VERSION ""

NS_ :

BS_:

BU_: FLZCU_VCU_EP FLZCU_PDCS_EP FLZCU_EP VCU_EP FLZCU_SignalRoute_EP BMS CDU FMCU_ISG FMCU ISG RMCU RMCU_E0V EVCC PDCS_EP PDCS_EP_E0V CIC_EP RmcuCdu RmcuCdu_E0V FmcuVcu_EP FmcuVcu_EP_E0V

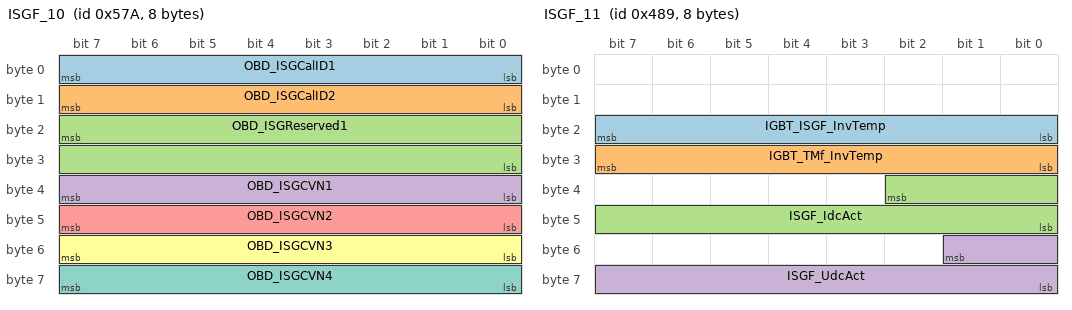
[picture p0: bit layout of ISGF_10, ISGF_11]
BO_ 1402 ISGF_10: 8 FMCU_ISG
 SG_ OBD_ISGCalID1 : 7|8@0+ (1,0) [0|255] ""  Vector__XXX
 SG_ OBD_ISGCalID2 : 15|8@0+ (1,0) [0|255] ""  Vector__XXX
 SG_ OBD_ISGReserved1 : 23|16@0+ (1,0) [0|65535] ""  Vector__XXX
 SG_ OBD_ISGCVN1 : 39|8@0+ (1,0) [0|255] ""  Vector__XXX
 SG_ OBD_ISGCVN2 : 47|8@0+ (1,0) [0|255] ""  Vector__XXX
 SG_ OBD_ISGCVN3 : 55|8@0+ (1,0) [0|255] ""  Vector__XXX
 SG_ OBD_ISGCVN4 : 63|8@0+ (1,0) [0|255] ""  Vector__XXX

BO_ 1161 ISGF_11: 8 FMCU_ISG
 SG_ IGBT_ISGF_InvTemp : 23|8@0+ (1,-40) [-40|213] "oC"  FLZCU_VCU_EP,VCU_EP,PDCS_EP,PDCS_EP_E0V
 SG_ IGBT_TMf_InvTemp : 31|8@0+ (1,-40) [-40|213] "oC"  Vector__XXX
 SG_ ISGF_IdcAct : 34|11@0+ (1,-1023) [-1023|1021] "A"  Vector__XXX
 SG_ ISGF_UdcAct : 49|10@0+ (1,0) [0|1021] "V"  Vector__XXX

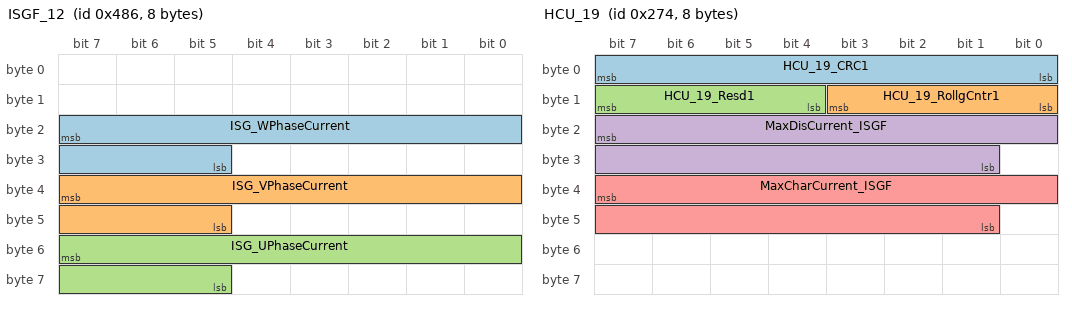
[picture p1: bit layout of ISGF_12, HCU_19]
BO_ 1158 ISGF_12: 8 FMCU_ISG
 SG_ ISG_WPhaseCurrent : 23|11@0+ (1,-1023) [-1023|1023] "A"  Vector__XXX
 SG_ ISG_VPhaseCurrent : 39|11@0+ (1,-1023) [-1023|1023] "A"  Vector__XXX
 SG_ ISG_UPhaseCurrent : 55|11@0+ (1,-1023) [-1023|1023] "A"  Vector__XXX

BO_ 327 ISGF_13: 24 FMCU_ISG
 SG_ ISGF_13_CRC : 7|8@0+ (1,0) [0|255] ""  FLZCU_VCU_EP,FLZCU_PDCS_EP,VCU_EP,PDCS_EP,PDCS_EP_E0V
 SG_ ISGF_13_RollgCntr : 11|4@0+ (1,0) [0|14] ""  FLZCU_VCU_EP,FLZCU_PDCS_EP,VCU_EP,PDCS_EP,PDCS_EP_E0V
 SG_ ISGF_IdcAct : 23|11@0+ (1,-1023) [-1023|1021] "A"  FLZCU_VCU_EP,FLZCU_PDCS_EP,VCU_EP,PDCS_EP,PDCS_EP_E0V
 SG_ ISGF_UdcAct : 39|10@0+ (1,0) [0|1021] "V"  FLZCU_VCU_EP,FLZCU_PDCS_EP,VCU_EP,PDCS_EP,PDCS_EP_E0V
 SG_ ISGF_ErrLvl : 27|4@0+ (1,0) [0|4] ""  FLZCU_VCU_EP,FLZCU_PDCS_EP,VCU_EP,PDCS_EP,PDCS_EP_E0V
 SG_ ISGF_VoltageT30 : 45|6@0+ (0.5,0) [0|31] "V"  FLZCU_VCU_EP,FLZCU_PDCS_EP,VCU_EP,PDCS_EP,PDCS_EP_E0V
 SG_ ISGF_DischargeState : 55|2@0+ (1,0) [0|3] ""  FLZCU_VCU_EP,FLZCU_PDCS_EP,VCU_EP,PDCS_EP,PDCS_EP_E0V
 SG_ ISGF_TrqActDampingReq : 50|11@0+ (0.25,-255) [-255|255] "Nm"  FLZCU_VCU_EP,FLZCU_PDCS_EP,VCU_EP,PDCS_EP,PDCS_EP_E0V
 SG_ ISGF_DampActive : 53|1@0+ (1,0) [0|1] ""  FLZCU_VCU_EP,FLZCU_PDCS_EP,VCU_EP,PDCS_EP,PDCS_EP_E0V
 SG_ ISGF_FlowReq : 87|8@0+ (0.1,0) [0|25.4] "L/min"  FLZCU_VCU_EP,FLZCU_PDCS_EP,VCU_EP,PDCS_EP,PDCS_EP_E0V
 SG_ ISGF_GateDrvSt : 95|2@0+ (1,0) [0|3] ""  FLZCU_VCU_EP,FLZCU_PDCS_EP,VCU_EP,PDCS_EP,PDCS_EP_E0V
 SG_ ISGF_WPhaseCurrent : 93|11@0+ (1,-1023) [-1023|1023] "A"  FLZCU_VCU_EP,FLZCU_PDCS_EP,VCU_EP,PDCS_EP,PDCS_EP_E0V
 SG_ ISGF_VPhaseCurrent : 98|11@0+ (1,-1023) [-1023|1023] "A"  FLZCU_VCU_EP,FLZCU_PDCS_EP,VCU_EP,PDCS_EP,PDCS_EP_E0V
 SG_ ISGF_UPhaseCurrent : 119|11@0+ (1,-1023) [-1023|1023] "A"  FLZCU_VCU_EP,FLZCU_PDCS_EP,VCU_EP,PDCS_EP,PDCS_EP_E0V
 SG_ ISGF_Fault1 : 151|9@0+ (1,0) [0|511] ""  FLZCU_VCU_EP,FLZCU_PDCS_EP,VCU_EP,PDCS_EP,PDCS_EP_E0V
 SG_ ISGF_Fault2 : 158|9@0+ (1,0) [0|511] ""  FLZCU_VCU_EP,FLZCU_PDCS_EP,VCU_EP,PDCS_EP,PDCS_EP_E0V
 SG_ ISGF_Fault3 : 165|9@0+ (1,0) [0|511] ""  FLZCU_VCU_EP,FLZCU_PDCS_EP,VCU_EP,PDCS_EP,PDCS_EP_E0V
 SG_ ISGF_Fault4 : 172|9@0+ (1,0) [0|511] ""  FLZCU_VCU_EP,FLZCU_PDCS_EP,VCU_EP,PDCS_EP,PDCS_EP_E0V

BO_ 1400 ISG_Version: 16 FMCU_ISG
 SG_ ISG_SupplierCode : 23|4@0+ (1,0) [0|15] ""  FLZCU_VCU_EP,FLZCU_PDCS_EP
 SG_ ISG_SwMajorVersion : 31|8@0+ (1,0) [0|255] ""  FLZCU_VCU_EP,FLZCU_PDCS_EP
 SG_ ISG_SwMinorVersion : 39|8@0+ (1,0) [0|255] ""  FLZCU_VCU_EP,FLZCU_PDCS_EP
 SG_ ISG_SwPatchVersion : 47|8@0+ (1,0) [0|255] ""  FLZCU_VCU_EP,FLZCU_PDCS_EP
 SG_ ISG_HwVersion : 87|48@0+ (1,0) [0|281474976710655] ""  FLZCU_VCU_EP,FLZCU_PDCS_EP

BO_ 264 HCU_7: 16 FLZCU_VCU_EP
 SG_ HCU_7_CRC1 : 7|8@0+ (1,0) [0|255] ""  FLZCU_PDCS_EP,FMCU_ISG,ISG
 SG_ HCU_7_RollgCntr1 : 11|4@0+ (1,0) [0|14] ""  FLZCU_PDCS_EP,FMCU_ISG,ISG
 SG_ HCU_7_Resd1 : 15|4@0+ (1,0) [0|15] ""  FLZCU_PDCS_EP,FMCU_ISG,ISG
 SG_ EngineTorqAct : 23|10@0+ (0.5,-150) [-150|350] "Nm"  FLZCU_PDCS_EP,FMCU_ISG,ISG
 SG_ HCU_ISGF_TorqSet : 29|11@0+ (0.25,-255) [-255|255] "Nm"  FLZCU_PDCS_EP,FMCU_ISG,ISG
 SG_ HCU_ISGF_TorqMax : 33|10@0+ (0.25,-25) [-25|230] "Nm"  FLZCU_PDCS_EP,FMCU_ISG,ISG
 SG_ HCU_ISGF_TorqMin : 55|10@0+ (0.25,-230) [-230|25] "Nm"  FLZCU_PDCS_EP,FMCU_ISG,ISG
 SG_ HCU_ISGF_ModeReq : 61|4@0+ (1,0) [0|15] ""  FLZCU_PDCS_EP,FMCU_ISG,ISG
 SG_ HCU_7_CRC2 : 71|8@0+ (1,0) [0|255] ""  FLZCU_PDCS_EP,FMCU_ISG,ISG
 SG_ HCU_7_RollgCntr2 : 75|4@0+ (1,0) [0|14] ""  FLZCU_PDCS_EP,FMCU_ISG,ISG
 SG_ HCU_7_Resd2 : 79|4@0+ (1,0) [0|15] ""  FLZCU_PDCS_EP,FMCU_ISG,ISG
 SG_ HCU_ISGF_SpdSet : 87|16@0+ (1,-32767) [-32767|32766] "rpm"  FLZCU_PDCS_EP,FMCU_ISG,ISG
 SG_ NGenrMaxInTqMode : 103|16@0+ (1,-32767) [-32767|32766] "rpm"  FLZCU_PDCS_EP,FMCU_ISG,ISG
 SG_ HCU_EngineSts : 116|1@0+ (1,0) [0|1] ""  FLZCU_PDCS_EP,FMCU_ISG,ISG
 SG_ HCU_SleepAllow : 117|1@0+ (1,0) [0|1] ""  FLZCU_PDCS_EP,FMCU_ISG,ISG
 SG_ HCU_ISGF_DampReq : 118|1@0+ (1,0) [0|1] ""  FLZCU_PDCS_EP,FMCU_ISG,ISG
 SG_ bEnaEmReq : 119|1@0+ (1,0) [0|1] ""  FLZCU_PDCS_EP,FMCU_ISG,ISG

BO_ 818 HCU_9: 16 FLZCU_VCU_EP
 SG_ HCU_9_CRC1 : 7|8@0+ (1,0) [0|255] ""  FLZCU_PDCS_EP,FMCU_ISG,ISG
 SG_ HCU_9_RollgCntr1 : 11|4@0+ (1,0) [0|14] ""  FLZCU_PDCS_EP,FMCU_ISG,ISG
 SG_ HCU_9_Resd1 : 15|4@0+ (1,0) [0|15] ""  FLZCU_PDCS_EP,FMCU_ISG,ISG
 SG_ HCU_ISGF_MaxTorqDampgCtl : 23|8@0+ (1,0) [0|253] "Nm"  FLZCU_PDCS_EP,FMCU_ISG,ISG
 SG_ HCU_ISGF_MaxTorqGradient : 31|14@0+ (32,0) [0|524192] ""  FLZCU_PDCS_EP,FMCU_ISG,ISG
 SG_ HCU_ISGF_Uset : 33|10@0+ (1,0) [0|1021] "V"  FLZCU_PDCS_EP,FMCU_ISG,ISG
 SG_ HCU_ISGF_Iset : 55|11@0+ (1,-1023) [-1023|1021] "A"  FLZCU_PDCS_EP,FMCU_ISG,ISG
 SG_ HCU_9_CRC2 : 71|8@0+ (1,0) [0|255] ""  FLZCU_PDCS_EP,FMCU_ISG,ISG
 SG_ HCU_9_RollgCntr2 : 75|4@0+ (1,0) [0|14] ""  FLZCU_PDCS_EP,FMCU_ISG,ISG
 SG_ HCU_9_Resd2 : 79|4@0+ (1,0) [0|15] ""  FLZCU_PDCS_EP,FMCU_ISG,ISG
 SG_ HCU_ISGF_LimpPwrReq : 87|8@0+ (0.1,0) [0|20] "KW"  FLZCU_PDCS_EP,FMCU_ISG,ISG
 SG_ HCU_EngStrtRes : 95|16@0+ (1,0) [0|65535] ""  FLZCU_PDCS_EP

BO_ 628 HCU_19: 8 FLZCU_VCU_EP
 SG_ HCU_19_CRC1 : 7|8@0+ (1,0) [0|255] ""  FMCU_ISG,ISG
 SG_ HCU_19_RollgCntr1 : 11|4@0+ (1,0) [0|14] ""  FMCU_ISG,ISG
 SG_ HCU_19_Resd1 : 15|4@0+ (1,0) [0|15] ""  FMCU_ISG,ISG
 SG_ MaxDisCurrent_ISGF : 23|15@0+ (0.05,0) [0|1023] "A"  FMCU_ISG,ISG
 SG_ MaxCharCurrent_ISGF : 39|15@0+ (0.05,-1023) [-1023|0] "A"  FMCU_ISG,ISG

BO_ 1034 HCU_1_G: 8 FLZCU_VCU_EP
 SG_ HCU_1_G_CRC1 : 7|8@0+ (1,0) [0|255] ""  FLZCU_PDCS_EP,BMS
 SG_ HCU_1_G_RollgCntr1 : 11|4@0+ (1,0) [0|14] ""  FLZCU_PDCS_EP,BMS
 SG_ HCU_1_G_Resd1 : 15|4@0+ (1,0) [0|15] ""  FLZCU_PDCS_EP,BMS
 SG_ HCU_EmPwr : 23|8@0+ (1,-128) [-100|100] "%"  FLZCU_PDCS_EP
 SG_ HCU_VehicleState : 27|4@0+ (1,0) [0|15] ""  FLZCU_PDCS_EP
 SG_ HCU_RunMode : 29|2@0+ (1,0) [0|3] ""  FLZCU_PDCS_EP,FMCU_ISG
 SG_ HCU_TMNumber : 31|2@0+ (1,0) [0|3] ""  FLZCU_PDCS_EP
 SG_ HCU_PwrTrnModeDisp : 34|3@0+ (1,0) [0|7] ""  FLZCU_PDCS_EP
 SG_ HCU_IntelligentPowerSupply : 37|3@0+ (1,0) [0|7] ""  FLZCU_PDCS_EP
 SG_ HCU_PowerModeFed : 39|2@0+ (1,0) [0|3] ""  FLZCU_PDCS_EP,BMS
 SG_ HCU_LimpHomeMode : 41|2@0+ (1,0) [0|3] ""  FLZCU_PDCS_EP
 SG_ HCU_ISGRegenerateSts : 42|1@0+ (1,0) [0|1] ""  FLZCU_PDCS_EP
 SG_ HCU_EmOverSpdWarn : 43|1@0+ (1,0) [0|1] ""  FLZCU_PDCS_EP
 SG_ HCU_PowertrainFault : 44|1@0+ (1,0) [0|1] ""  FLZCU_PDCS_EP
 SG_ HCU_PrePTReady : 45|1@0+ (1,0) [0|1] ""  FLZCU_PDCS_EP
 SG_ HCU_PowerModeChangeFail : 46|1@0+ (1,0) [0|1] ""  FLZCU_PDCS_EP
 SG_ BMSH_MILReq : 47|1@0+ (1,0) [0|1] ""  FLZCU_PDCS_EP
 SG_ TMF_EngMilLampReq : 48|1@0+ (1,0) [0|1] ""  FLZCU_PDCS_EP
 SG_ TMR_EngMilLampReq : 49|1@0+ (1,0) [0|1] ""  FLZCU_PDCS_EP
 SG_ HCU_MILReq : 50|1@0+ (1,0) [0|1] ""  FLZCU_PDCS_EP
 SG_ HCU_HVReady : 51|1@0+ (1,0) [0|1] ""  FLZCU_PDCS_EP
 SG_ HCU_PTReady : 52|1@0+ (1,0) [0|1] ""  FLZCU_PDCS_EP
 SG_ HCU_ChargingSts : 54|2@0+ (1,0) [0|3] ""  FLZCU_PDCS_EP,FMCU_ISG
 SG_ HCU_PtSts : 59|4@0+ (1,0) [0|15] ""  FLZCU_PDCS_EP,BMS
 SG_ HCU_InHbStrtRes : 63|4@0+ (1,0) [0|15] ""  FLZCU_PDCS_EP

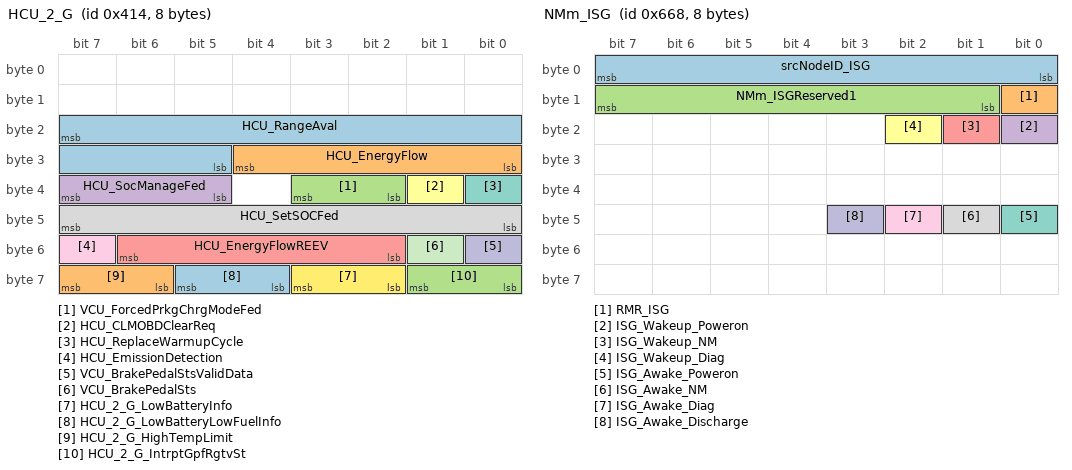
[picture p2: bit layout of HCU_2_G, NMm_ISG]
BO_ 1044 HCU_2_G: 8 FLZCU_VCU_EP
 SG_ HCU_RangeAval : 23|11@0+ (1,0) [0|2046] "KM"  Vector__XXX
 SG_ HCU_EnergyFlow : 28|5@0+ (1,0) [0|31] ""  Vector__XXX
 SG_ VCU_ForcedPrkgChrgModeFed : 35|2@0+ (1,0) [0|3] ""  Vector__XXX
 SG_ HCU_SocManageFed : 39|3@0+ (1,0) [0|7] ""  FLZCU_PDCS_EP,FLZCU_EP
 SG_ HCU_EnergyFlowREEV : 54|5@0+ (1,0) [0|31] ""  Vector__XXX
 SG_ HCU_CLMOBDClearReq : 33|1@0+ (1,0) [0|1] ""  Vector__XXX
 SG_ HCU_ReplaceWarmupCycle : 32|1@0+ (1,0) [0|1] ""  BMS,CDU,FMCU_ISG,FMCU,ISG,RMCU,RMCU_E0V,RmcuCdu,RmcuCdu_E0V
 SG_ HCU_SetSOCFed : 47|8@0+ (1,0) [0|100] ""  FLZCU_PDCS_EP,FLZCU_EP
 SG_ HCU_EmissionDetection : 55|1@0+ (1,0) [0|1] ""  Vector__XXX
 SG_ VCU_BrakePedalStsValidData : 48|1@0+ (1,0) [0|1] ""  FMCU_ISG
 SG_ VCU_BrakePedalSts : 49|1@0+ (1,0) [0|1] ""  FMCU_ISG
 SG_ HCU_2_G_LowBatteryInfo : 59|2@0+ (1,0) [0|3] ""  Vector__XXX
 SG_ HCU_2_G_LowBatteryLowFuelInfo : 61|2@0+ (1,0) [0|3] ""  Vector__XXX
 SG_ HCU_2_G_HighTempLimit : 63|2@0+ (1,0) [0|3] ""  Vector__XXX
 SG_ HCU_2_G_IntrptGpfRgtvSt : 57|2@0+ (1,0) [0|3] ""  Vector__XXX

BO_ 1640 NMm_ISG: 8 ISG
 SG_ srcNodeID_ISG : 7|8@0+ (1,0) [0|255] ""  FLZCU_VCU_EP,FLZCU_PDCS_EP
 SG_ RMR_ISG : 8|1@0+ (1,0) [0|1] ""  FLZCU_VCU_EP,FLZCU_PDCS_EP
 SG_ NMm_ISGReserved1 : 15|7@0+ (1,0) [0|127] ""  FLZCU_VCU_EP,FLZCU_PDCS_EP
 SG_ ISG_Wakeup_Poweron : 16|1@0+ (1,0) [0|1] ""  FLZCU_VCU_EP,FLZCU_PDCS_EP
 SG_ ISG_Wakeup_NM : 17|1@0+ (1,0) [0|1] ""  FLZCU_VCU_EP,FLZCU_PDCS_EP
 SG_ ISG_Wakeup_Diag : 18|1@0+ (1,0) [0|1] ""  FLZCU_VCU_EP,FLZCU_PDCS_EP
 SG_ ISG_Awake_Poweron : 40|1@0+ (1,0) [0|1] ""  FLZCU_VCU_EP,FLZCU_PDCS_EP
 SG_ ISG_Awake_NM : 41|1@0+ (1,0) [0|1] ""  FLZCU_VCU_EP,FLZCU_PDCS_EP
 SG_ ISG_Awake_Diag : 42|1@0+ (1,0) [0|1] ""  FLZCU_VCU_EP,FLZCU_PDCS_EP
 SG_ ISG_Awake_Discharge : 43|1@0+ (1,0) [0|1] ""  FLZCU_VCU_EP,FLZCU_PDCS_EP

BO_ 1947 Diag_ISG_RES: 64 ISG
 SG_ Diag_ISG_RES : 7|64@0+ (1,0) [0|18446744073709551615] ""  Vector__XXX

BO_ 2028 Diag_OBD_ISG_RES: 64 FMCU_ISG
 SG_ Diag_OBD_ISG_RES : 7|64@0+ (1,0) [0|18446744073709551615] ""  Vector__XXX

BO_ 2026 Diag_OBD_BMS_RES: 64 BMS
 SG_ Diag_OBD_BMS_RES : 7|64@0+ (1,0) [0|18446744073709551615] ""  Vector__XXX

BO_ 2030 Diag_OBD_CDU_RES: 64 CDU
 SG_ Diag_OBD_CDU_RES : 7|64@0+ (1,0) [0|18446744073709551615] ""  Vector__XXX

BO_ 2027 Diag_OBD_RMCU_RES: 64 RMCU
 SG_ Diag_OBD_RMCU_RES : 7|64@0+ (1,0) [0|18446744073709551615] ""  Vector__XXX

BO_ 1819 Diag_ISG_REQ: 64 Vector__XXX
 SG_ Diag_ISG_REQ : 7|64@0+ (1,0) [0|18446744073709551615] ""  ISG

BO_ 2020 Diag_OBD_ISG_REQ: 64 Vector__XXX
 SG_ Diag_OBD_ISG_REQ : 7|64@0+ (1,0) [0|18446744073709551615] ""  FMCU_ISG,ISG

BO_ 2018 Diag_OBD_BMS_REQ: 64 Vector__XXX
 SG_ Diag_BMS_REQ : 7|64@0+ (1,0) [0|18446744073709551615] ""  BMS

BO_ 2022 Diag_OBD_CDU_REQ: 64 Vector__XXX
 SG_ Diag_CDU_REQ : 7|64@0+ (1,0) [0|18446744073709551615] ""  CDU

BO_ 2019 Diag_OBD_RMCU_REQ: 64 Vector__XXX
 SG_ Diag_RMCU_REQ : 7|64@0+ (1,0) [0|18446744073709551615] ""  RMCU,RMCU_E0V,RmcuCdu,RmcuCdu_E0V

BO_TX_BU_ 1161 : FMCU_ISG,ISG;

BO_TX_BU_ 327 : FMCU_ISG,ISG;

BO_TX_BU_ 1400 : FMCU_ISG,ISG;

BO_TX_BU_ 264 : FLZCU_VCU_EP,VCU_EP,PDCS_EP,PDCS_EP_E0V,FmcuVcu_EP,FmcuVcu_EP_E0V;

BO_TX_BU_ 818 : FLZCU_VCU_EP,VCU_EP,PDCS_EP,PDCS_EP_E0V,FmcuVcu_EP,FmcuVcu_EP_E0V;

BO_TX_BU_ 628 : FLZCU_VCU_EP,VCU_EP,PDCS_EP,PDCS_EP_E0V,FmcuVcu_EP,FmcuVcu_EP_E0V;

BO_TX_BU_ 1034 : FLZCU_VCU_EP,VCU_EP,PDCS_EP,PDCS_EP_E0V,FmcuVcu_EP,FmcuVcu_EP_E0V;

BO_TX_BU_ 1044 : FLZCU_VCU_EP,VCU_EP,PDCS_EP,PDCS_EP_E0V,FmcuVcu_EP,FmcuVcu_EP_E0V;

BO_TX_BU_ 2028 : FMCU_ISG,ISG;

BO_TX_BU_ 2027 : RMCU,RMCU_E0V,RmcuCdu,RmcuCdu_E0V;
CM_ BO_ 1947 "8~64�ֽ�����Ӧ";
CM_ BO_ 2028 "8~64�ֽ�����Ӧ";
CM_ BO_ 2026 "8~64�ֽ�����Ӧ";
CM_ BO_ 2030 "8~64�ֽ�����Ӧ";
CM_ BO_ 2027 "8~64�ֽ�����Ӧ";
CM_ BO_ 1819 "8~64�ֽ�����Ӧ";
CM_ BO_ 2020 "8~64�ֽ�����Ӧ";
CM_ BO_ 2018 "8~64�ֽ�����Ӧ";
CM_ BO_ 2022 "8~64�ֽ�����Ӧ";
CM_ BO_ 2019 "8~64�ֽ�����Ӧ";
CM_ SG_ 1402 OBD_ISGCalID1 "ISG Calibration ID1";
CM_ SG_ 1402 OBD_ISGCalID2 "ISG Calibration ID2";
CM_ SG_ 1402 OBD_ISGCVN1 "ISG CVN1";
CM_ SG_ 1402 OBD_ISGCVN2 "ISG CVN2";
CM_ SG_ 1402 OBD_ISGCVN3 "ISG CVN3";
CM_ SG_ 1402 OBD_ISGCVN4 "ISG CVN4";
CM_ SG_ 1161 IGBT_ISGF_InvTemp "Inverter temperature";
CM_ SG_ 1161 IGBT_TMf_InvTemp "Inverter temperature";
CM_ SG_ 1161 ISGF_IdcAct "actual HV current at generator";
CM_ SG_ 1161 ISGF_UdcAct "actual bus voltage";
CM_ SG_ 1158 ISG_WPhaseCurrent "W Phase current";
CM_ SG_ 1158 ISG_VPhaseCurrent "V Phase current";
CM_ SG_ 1158 ISG_UPhaseCurrent "U Phase current";
CM_ SG_ 327 ISGF_13_CRC "Profile1A:E2E CRC (SAE J1850 CRC-8) for 8 Bytes
DataID:0x00A7";
CM_ SG_ 327 ISGF_13_RollgCntr "Profile1A:E2E Rolling message counter(the maximum value of Alive counter is 14)";
CM_ SG_ 327 ISGF_IdcAct "actual HV current at generator �������������̣�";
CM_ SG_ 327 ISGF_UdcAct "actual bus voltage ��ѹ���������̣�";
CM_ SG_ 327 ISGF_ErrLvl "Error Level ���ϵȼ����������̣�";
CM_ SG_ 327 ISGF_VoltageT30 "KL30 sampling value KL30�����ֵ���������̣�";
CM_ SG_ 327 ISGF_DischargeState "Active discharge state of ISG �ŵ�״̬���������̣�";
CM_ SG_ 327 ISGF_TrqActDampingReq "Active damping requirement ��������Ť������ֵ���������̣�";
CM_ SG_ 327 ISGF_DampActive "Damping state of ISG motor ��������״̬���������̣�";
CM_ SG_ 327 ISGF_FlowReq "water flow request ISG������ȴˮ�������������̣�";
CM_ SG_ 327 ISGF_GateDrvSt "state of gate driver �ż�����״̬���������̣�";
CM_ SG_ 327 ISGF_WPhaseCurrent "W Phase current";
CM_ SG_ 327 ISGF_VPhaseCurrent "V Phase current";
CM_ SG_ 327 ISGF_UPhaseCurrent "U Phase current";
CM_ SG_ 327 ISGF_Fault1 "refre to DTC Matrix:ISG Fault ErroCode1 �����루�������̣�";
CM_ SG_ 327 ISGF_Fault2 "refre to DTC Matrix:ISG Fault ErroCode2 �����루�������̣�";
CM_ SG_ 327 ISGF_Fault3 "refre to DTC Matrix:ISG Fault ErroCode3 �����루�������̣�";
CM_ SG_ 327 ISGF_Fault4 "refre to DTC Matrix:ISG Fault ErroCode4 �����루�������̣�";
CM_ SG_ 1400 ISG_SupplierCode "Supplier Code of ISG ��Ӧ�̴��루�������̣�";
CM_ SG_ 1400 ISG_SwMajorVersion "Software major version of ISG ����汾Major���֣��������̣�";
CM_ SG_ 1400 ISG_SwMinorVersion "Software minor version of ISG ����汾Minor���֣��������̣�";
CM_ SG_ 1400 ISG_SwPatchVersion "Software patch version of ISG ����汾Patch���֣��������̣�";
CM_ SG_ 1400 ISG_HwVersion "Hardware version of ISG Ӳ���汾���������̣�";
CM_ SG_ 264 HCU_7_CRC1 "Profile1A:E2E CRC (SAE J1850 CRC-8) for 8 Bytes
DataID:0x0095";
CM_ SG_ 264 HCU_7_RollgCntr1 "Profile1A:E2E Rolling message counter(the maximum value of Alive counter is 14)";
CM_ SG_ 264 HCU_7_Resd1 "Profile1A:E2E Reserved";
CM_ SG_ 264 EngineTorqAct "Actual engine Torque(current conditions incl. intervention)
������ʵ��Ť��";
CM_ SG_ 264 HCU_ISGF_TorqSet "torque command";
CM_ SG_ 264 HCU_ISGF_TorqMax "max limit of positive torque for drive";
CM_ SG_ 264 HCU_ISGF_TorqMin "max limit of negative torque for drive";
CM_ SG_ 264 HCU_ISGF_ModeReq "state/mode request of ISG motor";
CM_ SG_ 264 HCU_7_CRC2 "Profile1A:E2E CRC (SAE J1850 CRC-8) for 8 Bytes
DataID:0x0096";
CM_ SG_ 264 HCU_7_RollgCntr2 "Profile1A:E2E Rolling message counter(the maximum value of Alive counter is 14)";
CM_ SG_ 264 HCU_7_Resd2 "Profile1A:E2E Reserved";
CM_ SG_ 264 HCU_ISGF_SpdSet "speed command";
CM_ SG_ 264 NGenrMaxInTqMode "speed limit request in torque mode";
CM_ SG_ 264 HCU_EngineSts "actual engine status";
CM_ SG_ 264 HCU_SleepAllow "sleep allow command";
CM_ SG_ 264 HCU_ISGF_DampReq "damp request";
CM_ SG_ 264 bEnaEmReq "ISG enable request";
CM_ SG_ 818 HCU_9_CRC1 "Profile1A:E2E CRC (SAE J1850 CRC-8) for 8 Bytes
DataID:0x0097";
CM_ SG_ 818 HCU_9_RollgCntr1 "Profile1A:E2E Rolling message counter(the maximum value of Alive counter is 14)";
CM_ SG_ 818 HCU_9_Resd1 "Profile1A:E2E Reserved";
CM_ SG_ 818 HCU_ISGF_MaxTorqDampgCtl "Maximum limit for damping torque";
CM_ SG_ 818 HCU_ISGF_MaxTorqGradient "Maximum change rate of the torque request";
CM_ SG_ 818 HCU_ISGF_Uset "Voltage Set";
CM_ SG_ 818 HCU_ISGF_Iset "Current Set";
CM_ SG_ 818 HCU_9_CRC2 "Profile1A:E2E CRC (SAE J1850 CRC-8) for 8 Bytes
DataID:0x0098";
CM_ SG_ 818 HCU_9_RollgCntr2 "Profile1A:E2E Rolling message counter(the maximum value of Alive counter is 14)";
CM_ SG_ 818 HCU_9_Resd2 "Profile1A:E2E Reserved";
CM_ SG_ 818 HCU_ISGF_LimpPwrReq "Limp power request";
CM_ SG_ 818 HCU_EngStrtRes "ISG enable request";
CM_ SG_ 628 HCU_19_CRC1 "Profile1A:E2E CRC (SAE J1850 CRC-8) for 8 Bytes
DataID:0x0099";
CM_ SG_ 628 HCU_19_RollgCntr1 "Profile1A:E2E Rolling message counter(the maximum value of Alive counter is 14)";
CM_ SG_ 628 HCU_19_Resd1 "Profile1A:E2E Reserved";
CM_ SG_ 628 MaxDisCurrent_ISGF "��������ŵ��������";
CM_ SG_ 628 MaxCharCurrent_ISGF "�����������������";
CM_ SG_ 1034 HCU_1_G_CRC1 "Profile1A:E2E CRC (SAE J1850 CRC-8) for 8 Bytes
DataID:0x009A";
CM_ SG_ 1034 HCU_1_G_RollgCntr1 "Profile1A:E2E Rolling message counter(the maximum value of Alive counter is 14)";
CM_ SG_ 1034 HCU_1_G_Resd1 "Profile1A:E2E Reserved";
CM_ SG_ 1034 HCU_EmPwr "E-Motor power indication";
CM_ SG_ 1034 HCU_RunMode "PHEV����32960�����ϴ��ô��ź�";
CM_ SG_ 1034 HCU_PwrTrnModeDisp "Powertrain mode for displaying energy flow";
CM_ SG_ 1034 HCU_IntelligentPowerSupply "Intelligent Power Supply For small battery";
CM_ SG_ 1034 HCU_PowerModeFed "Power mode Feedback";
CM_ SG_ 1034 HCU_LimpHomeMode "HCU sends limphome function indication to ICM   REEV Only, for dual-clutch problem";
CM_ SG_ 1034 HCU_PowertrainFault "Powertrain fault";
CM_ SG_ 1034 HCU_PowerModeChangeFail "(Once triggered,send 5 frames 'Active 'immediately, then send 'No active')";
CM_ SG_ 1034 BMSH_MILReq "BMS MIL������";
CM_ SG_ 1034 TMF_EngMilLampReq "MIL lamp on request(TMF)";
CM_ SG_ 1034 TMR_EngMilLampReq "MIL lamp on request(TMR)";
CM_ SG_ 1034 HCU_MILReq "MIL lamp on request(HCU)";
CM_ SG_ 1034 HCU_HVReady "HV Ready indication";
CM_ SG_ 1034 HCU_PTReady "Drive Ready indication";
CM_ SG_ 1034 HCU_ChargingSts "charge status";
CM_ SG_ 1034 HCU_PtSts "��������״̬";
CM_ SG_ 1034 HCU_InHbStrtRes "��ֹ������ԭ��";
CM_ SG_ 1044 HCU_RangeAval "Range Available";
CM_ SG_ 1044 HCU_EnergyFlow "Energy Flow";
CM_ SG_ 1044 VCU_ForcedPrkgChrgModeFed "פ����練��";
CM_ SG_ 1044 HCU_SocManageFed "Soc Manage Feedback
0x4:ForcedEVMode(E02��Ŀ)";
CM_ SG_ 1044 HCU_EnergyFlowREEV "REEV Energy Flow������������
REEV,BEV����32960�����ϴ��ô��ź�";
CM_ SG_ 1044 HCU_CLMOBDClearReq "Mode $04 clear OBD information request flag
����$04 ����������ʱ��HCU���ڷ���0x1 Request�����յ�CLM�������������״̬���ʱ���ٷ�0x0 No Request";
CM_ SG_ 1044 HCU_ReplaceWarmupCycle "Replace warm-up cycle ���ů��ѭ��";
CM_ SG_ 1044 HCU_SetSOCFed "Set SOC Feedback";
CM_ SG_ 1044 HCU_EmissionDetection "�ŷż��ģʽ״̬";
CM_ SG_ 1044 HCU_2_G_LowBatteryInfo "No Request  ������ʾ
Request  ������ʾ��������ص������ͣ���������ǹ�����л���Ready��硱";
CM_ SG_ 1044 HCU_2_G_LowBatteryLowFuelInfo "No Request ������ʾ
Request ������ʾ���������������ͣ����������ͻ��硱";
CM_ SG_ 1044 HCU_2_G_HighTempLimit "δ����
��������";
CM_ SG_ 1044 HCU_2_G_IntrptGpfRgtvSt "Interrupt GPF Regenerativestate";
CM_ SG_ 1640 RMR_ISG "If set to 1 to force the network management of all other nodes on the bus into the re-peat message state.";
CM_ SG_ 1640 ISG_Wakeup_Poweron "KL15 ON";
CM_ SG_ 1640 ISG_Wakeup_NM "NM����";
CM_ SG_ 1640 ISG_Wakeup_Diag "Wakeup Source3";
CM_ SG_ 1640 ISG_Awake_Poweron "KL15 ON";
CM_ SG_ 1640 ISG_Awake_NM "Awake Reason2";
CM_ SG_ 1640 ISG_Awake_Diag "���յ���������ص���ϱ���";
CM_ SG_ 1640 ISG_Awake_Discharge "�ŵ����ҷŵ�δ��ʱ";

BA_DEF_ BO_  "NmMessage" ENUM "No","Yes";
BA_DEF_ BO_  "DiagState" ENUM  "No","Yes";
BA_DEF_ BO_  "GenMsgSendType" ENUM  "Cyclic","Event","IfActive","CE","CA","NoMsgSendType";
BA_DEF_ BO_  "GenMsgCycleTime" INT 0 0;
BA_DEF_ SG_  "GenSigSendType" ENUM  "Cyclic","OnChange","OnWrite","IfActive","OnChangeWithRepetition","OnWriteWithRepetition","IfActiveWithRepetition","NoSigSendType","OnChangeAndIfActive","OnChangeAndIfActiveWithRepetition","CA","CE","Event";
BA_DEF_ SG_  "GenSigStartValue" INT 0 0;
BA_DEF_ SG_  "GenSigInactiveValue" INT 0 0;
BA_DEF_ BO_  "GenMsgCycleTimeFast" INT 0 0;
BA_DEF_ BO_  "GenMsgNrOfRepetition" INT 0 0;
BA_DEF_ BO_  "GenMsgDelayTime" INT 0 0;
BA_DEF_ BO_  "CANFD_BRS" ENUM  "0","1";
BA_DEF_ BO_  "VFrameFormat" ENUM  "StandardCAN","ExtendedCAN","reserved","reserved","reserved","reserved","reserved","reserved","reserved","reserved","reserved","reserved","reserved","reserved","StandardCAN_FD","ExtendedCAN_FD";
BA_DEF_ BO_  "GenMsgILSupport" ENUM  "No","Yes";
BA_DEF_ SG_ "GenSigASIL" ENUM "QM","A","B","C","D","";
BA_DEF_DEF_  "NmMessage" "No";
BA_DEF_DEF_  "DiagState" "No";
BA_DEF_DEF_  "GenMsgSendType" "Cyclic";
BA_DEF_DEF_  "GenMsgCycleTime" 0;
BA_DEF_DEF_  "GenSigSendType" "Cyclic";
BA_DEF_DEF_  "GenSigStartValue" 0;
BA_DEF_DEF_  "GenSigInactiveValue" 0;
BA_DEF_DEF_  "GenMsgCycleTimeFast" 0;
BA_DEF_DEF_  "GenMsgNrOfRepetition" 0;
BA_DEF_DEF_  "GenMsgDelayTime" 0;
BA_DEF_DEF_  "CANFD_BRS" "1";
BA_DEF_DEF_  "VFrameFormat" "StandardCAN_FD";
BA_DEF_DEF_  "GenMsgILSupport" "No";
BA_DEF_DEF_ "GenSigASIL" "QM";
BA_ "GenMsgILSupport" BO_ 1402 1;
BA_ "GenMsgCycleTime" BO_ 1402 1000;
BA_ "GenSigASIL"  SG_ 1402 OBD_ISGCalID1 5;
BA_ "GenSigASIL"  SG_ 1402 OBD_ISGCalID2 5;
BA_ "GenSigASIL"  SG_ 1402 OBD_ISGReserved1 5;
BA_ "GenSigASIL"  SG_ 1402 OBD_ISGCVN1 5;
BA_ "GenSigASIL"  SG_ 1402 OBD_ISGCVN2 5;
BA_ "GenSigASIL"  SG_ 1402 OBD_ISGCVN3 5;
BA_ "GenSigASIL"  SG_ 1402 OBD_ISGCVN4 5;
BA_ "GenMsgILSupport" BO_ 1161 1;
BA_ "GenMsgCycleTime" BO_ 1161 1000;
BA_ "GenSigStartValue" SG_ 1161 IGBT_ISGF_InvTemp 40;
BA_ "GenSigASIL"  SG_ 1161 IGBT_ISGF_InvTemp 5;
BA_ "GenSigStartValue" SG_ 1161 IGBT_TMf_InvTemp 40;
BA_ "GenSigASIL"  SG_ 1161 IGBT_TMf_InvTemp 5;
BA_ "GenSigStartValue" SG_ 1161 ISGF_IdcAct 1023;
BA_ "GenSigASIL"  SG_ 1161 ISGF_IdcAct 5;
BA_ "GenSigASIL"  SG_ 1161 ISGF_UdcAct 5;
BA_ "GenMsgILSupport" BO_ 1158 1;
BA_ "GenMsgCycleTime" BO_ 1158 1000;
BA_ "GenSigASIL"  SG_ 1158 ISG_WPhaseCurrent 5;
BA_ "GenSigASIL"  SG_ 1158 ISG_VPhaseCurrent 5;
BA_ "GenSigASIL"  SG_ 1158 ISG_UPhaseCurrent 5;
BA_ "GenMsgILSupport" BO_ 327 1;
BA_ "GenMsgCycleTime" BO_ 327 10;
BA_ "GenSigASIL"  SG_ 327 ISGF_13_CRC 5;
BA_ "GenSigASIL"  SG_ 327 ISGF_13_RollgCntr 5;
BA_ "GenSigStartValue" SG_ 327 ISGF_IdcAct 1023;
BA_ "GenSigASIL"  SG_ 327 ISGF_IdcAct 5;
BA_ "GenSigASIL"  SG_ 327 ISGF_UdcAct 5;
BA_ "GenSigASIL"  SG_ 327 ISGF_ErrLvl 5;
BA_ "GenSigASIL"  SG_ 327 ISGF_VoltageT30 5;
BA_ "GenSigASIL"  SG_ 327 ISGF_DischargeState 5;
BA_ "GenSigStartValue" SG_ 327 ISGF_TrqActDampingReq 1020;
BA_ "GenSigASIL"  SG_ 327 ISGF_TrqActDampingReq 5;
BA_ "GenSigASIL"  SG_ 327 ISGF_DampActive 5;
BA_ "GenSigASIL"  SG_ 327 ISGF_FlowReq 5;
BA_ "GenSigASIL"  SG_ 327 ISGF_GateDrvSt 5;
BA_ "GenSigASIL"  SG_ 327 ISGF_WPhaseCurrent 5;
BA_ "GenSigASIL"  SG_ 327 ISGF_VPhaseCurrent 5;
BA_ "GenSigASIL"  SG_ 327 ISGF_UPhaseCurrent 5;
BA_ "GenSigASIL"  SG_ 327 ISGF_Fault1 5;
BA_ "GenSigASIL"  SG_ 327 ISGF_Fault2 5;
BA_ "GenSigASIL"  SG_ 327 ISGF_Fault3 5;
BA_ "GenSigASIL"  SG_ 327 ISGF_Fault4 5;
BA_ "GenMsgILSupport" BO_ 1400 1;
BA_ "GenMsgCycleTime" BO_ 1400 1000;
BA_ "GenSigASIL"  SG_ 1400 ISG_SupplierCode 5;
BA_ "GenSigASIL"  SG_ 1400 ISG_SwMajorVersion 5;
BA_ "GenSigASIL"  SG_ 1400 ISG_SwMinorVersion 5;
BA_ "GenSigASIL"  SG_ 1400 ISG_SwPatchVersion 5;
BA_ "GenSigASIL"  SG_ 1400 ISG_HwVersion 5;
BA_ "GenMsgILSupport" BO_ 264 1;
BA_ "GenMsgCycleTime" BO_ 264 10;
BA_ "GenSigASIL"  SG_ 264 HCU_7_CRC1 5;
BA_ "GenSigASIL"  SG_ 264 HCU_7_RollgCntr1 5;
BA_ "GenSigASIL"  SG_ 264 HCU_7_Resd1 5;
BA_ "GenSigStartValue" SG_ 264 EngineTorqAct 300;
BA_ "GenSigASIL"  SG_ 264 EngineTorqAct 1;
BA_ "GenSigStartValue" SG_ 264 HCU_ISGF_TorqSet 1020;
BA_ "GenSigASIL"  SG_ 264 HCU_ISGF_TorqSet 1;
BA_ "GenSigASIL"  SG_ 264 HCU_ISGF_TorqMax 1;
BA_ "GenSigStartValue" SG_ 264 HCU_ISGF_TorqMin 1020;
BA_ "GenSigASIL"  SG_ 264 HCU_ISGF_TorqMin 1;
BA_ "GenSigASIL"  SG_ 264 HCU_ISGF_ModeReq 1;
BA_ "GenSigASIL"  SG_ 264 HCU_7_CRC2 5;
BA_ "GenSigASIL"  SG_ 264 HCU_7_RollgCntr2 5;
BA_ "GenSigASIL"  SG_ 264 HCU_7_Resd2 5;
BA_ "GenSigStartValue" SG_ 264 HCU_ISGF_SpdSet 32767;
BA_ "GenSigASIL"  SG_ 264 HCU_ISGF_SpdSet 1;
BA_ "GenSigStartValue" SG_ 264 NGenrMaxInTqMode 32767;
BA_ "GenSigASIL"  SG_ 264 NGenrMaxInTqMode 1;
BA_ "GenSigASIL"  SG_ 264 HCU_EngineSts 1;
BA_ "GenSigASIL"  SG_ 264 HCU_SleepAllow 1;
BA_ "GenSigASIL"  SG_ 264 HCU_ISGF_DampReq 1;
BA_ "GenSigASIL"  SG_ 264 bEnaEmReq 1;
BA_ "GenMsgILSupport" BO_ 818 1;
BA_ "GenMsgCycleTime" BO_ 818 50;
BA_ "GenSigASIL"  SG_ 818 HCU_9_CRC1 5;
BA_ "GenSigASIL"  SG_ 818 HCU_9_RollgCntr1 5;
BA_ "GenSigASIL"  SG_ 818 HCU_9_Resd1 5;
BA_ "GenSigASIL"  SG_ 818 HCU_ISGF_MaxTorqDampgCtl 1;
BA_ "GenSigASIL"  SG_ 818 HCU_ISGF_MaxTorqGradient 1;
BA_ "GenSigASIL"  SG_ 818 HCU_ISGF_Uset 1;
BA_ "GenSigStartValue" SG_ 818 HCU_ISGF_Iset 1023;
BA_ "GenSigASIL"  SG_ 818 HCU_ISGF_Iset 1;
BA_ "GenSigASIL"  SG_ 818 HCU_9_CRC2 5;
BA_ "GenSigASIL"  SG_ 818 HCU_9_RollgCntr2 5;
BA_ "GenSigASIL"  SG_ 818 HCU_9_Resd2 5;
BA_ "GenSigASIL"  SG_ 818 HCU_ISGF_LimpPwrReq 1;
BA_ "GenSigASIL"  SG_ 818 HCU_EngStrtRes 1;
BA_ "GenMsgILSupport" BO_ 628 1;
BA_ "GenMsgCycleTime" BO_ 628 20;
BA_ "GenSigASIL"  SG_ 628 HCU_19_CRC1 5;
BA_ "GenSigASIL"  SG_ 628 HCU_19_RollgCntr1 5;
BA_ "GenSigASIL"  SG_ 628 HCU_19_Resd1 5;
BA_ "GenSigASIL"  SG_ 628 MaxDisCurrent_ISGF 1;
BA_ "GenSigStartValue" SG_ 628 MaxCharCurrent_ISGF 20460;
BA_ "GenSigASIL"  SG_ 628 MaxCharCurrent_ISGF 1;
BA_ "GenMsgILSupport" BO_ 1034 1;
BA_ "GenMsgCycleTime" BO_ 1034 100;
BA_ "GenSigASIL"  SG_ 1034 HCU_1_G_CRC1 5;
BA_ "GenSigASIL"  SG_ 1034 HCU_1_G_RollgCntr1 5;
BA_ "GenSigASIL"  SG_ 1034 HCU_1_G_Resd1 5;
BA_ "GenSigStartValue" SG_ 1034 HCU_EmPwr 128;
BA_ "GenSigASIL"  SG_ 1034 HCU_EmPwr 5;
BA_ "GenSigASIL"  SG_ 1034 HCU_VehicleState 1;
BA_ "GenSigASIL"  SG_ 1034 HCU_RunMode 5;
BA_ "GenSigASIL"  SG_ 1034 HCU_TMNumber 5;
BA_ "GenSigASIL"  SG_ 1034 HCU_PwrTrnModeDisp 5;
BA_ "GenSigASIL"  SG_ 1034 HCU_IntelligentPowerSupply 5;
BA_ "GenSigASIL"  SG_ 1034 HCU_PowerModeFed 1;
BA_ "GenSigASIL"  SG_ 1034 HCU_LimpHomeMode 1;
BA_ "GenSigASIL"  SG_ 1034 HCU_ISGRegenerateSts 5;
BA_ "GenSigASIL"  SG_ 1034 HCU_EmOverSpdWarn 5;
BA_ "GenSigASIL"  SG_ 1034 HCU_PowertrainFault 5;
BA_ "GenSigASIL"  SG_ 1034 HCU_PrePTReady 1;
BA_ "GenSigASIL"  SG_ 1034 HCU_PowerModeChangeFail 5;
BA_ "GenSigASIL"  SG_ 1034 BMSH_MILReq 1;
BA_ "GenSigASIL"  SG_ 1034 TMF_EngMilLampReq 1;
BA_ "GenSigASIL"  SG_ 1034 TMR_EngMilLampReq 1;
BA_ "GenSigASIL"  SG_ 1034 HCU_MILReq 1;
BA_ "GenSigASIL"  SG_ 1034 HCU_HVReady 1;
BA_ "GenSigASIL"  SG_ 1034 HCU_PTReady 1;
BA_ "GenSigASIL"  SG_ 1034 HCU_ChargingSts 5;
BA_ "GenSigASIL"  SG_ 1034 HCU_PtSts 5;
BA_ "GenSigASIL"  SG_ 1034 HCU_InHbStrtRes 5;
BA_ "GenMsgILSupport" BO_ 1044 1;
BA_ "GenMsgCycleTime" BO_ 1044 100;
BA_ "GenSigASIL"  SG_ 1044 HCU_RangeAval 5;
BA_ "GenSigASIL"  SG_ 1044 HCU_EnergyFlow 5;
BA_ "GenSigASIL"  SG_ 1044 VCU_ForcedPrkgChrgModeFed 5;
BA_ "GenSigASIL"  SG_ 1044 HCU_SocManageFed 5;
BA_ "GenSigASIL"  SG_ 1044 HCU_EnergyFlowREEV 5;
BA_ "GenSigASIL"  SG_ 1044 HCU_CLMOBDClearReq 5;
BA_ "GenSigASIL"  SG_ 1044 HCU_ReplaceWarmupCycle 5;
BA_ "GenSigASIL"  SG_ 1044 HCU_SetSOCFed 5;
BA_ "GenSigASIL"  SG_ 1044 HCU_EmissionDetection 5;
BA_ "GenSigASIL"  SG_ 1044 VCU_BrakePedalStsValidData 5;
BA_ "GenSigASIL"  SG_ 1044 VCU_BrakePedalSts 5;
BA_ "GenSigASIL"  SG_ 1044 HCU_2_G_LowBatteryInfo 5;
BA_ "GenSigASIL"  SG_ 1044 HCU_2_G_LowBatteryLowFuelInfo 5;
BA_ "GenSigASIL"  SG_ 1044 HCU_2_G_HighTempLimit 5;
BA_ "GenSigASIL"  SG_ 1044 HCU_2_G_IntrptGpfRgtvSt 5;
BA_ "NmMessage" BO_ 1640 1;
BA_ "GenMsgCycleTime" BO_ 1640 1000;
BA_ "CANFD_BRS" BO_ 1640 0;
BA_ "VFrameFormat" BO_ 1640 0;
BA_ "GenSigStartValue" SG_ 1640 srcNodeID_ISG 104;
BA_ "GenSigASIL"  SG_ 1640 srcNodeID_ISG 5;
BA_ "GenSigASIL"  SG_ 1640 RMR_ISG 5;
BA_ "GenSigASIL"  SG_ 1640 NMm_ISGReserved1 5;
BA_ "GenSigASIL"  SG_ 1640 ISG_Wakeup_Poweron 5;
BA_ "GenSigASIL"  SG_ 1640 ISG_Wakeup_NM 5;
BA_ "GenSigASIL"  SG_ 1640 ISG_Wakeup_Diag 5;
BA_ "GenSigASIL"  SG_ 1640 ISG_Awake_Poweron 5;
BA_ "GenSigASIL"  SG_ 1640 ISG_Awake_NM 5;
BA_ "GenSigASIL"  SG_ 1640 ISG_Awake_Diag 5;
BA_ "GenSigASIL"  SG_ 1640 ISG_Awake_Discharge 5;
BA_ "GenMsgSendType" BO_ 1947 1;
BA_ "GenSigSendType" SG_ 1947 Diag_ISG_RES 2;
BA_ "GenSigASIL"  SG_ 1947 Diag_ISG_RES 5;
BA_ "GenMsgSendType" BO_ 2028 1;
BA_ "GenSigSendType" SG_ 2028 Diag_OBD_ISG_RES 2;
BA_ "GenSigASIL"  SG_ 2028 Diag_OBD_ISG_RES 5;
BA_ "GenMsgSendType" BO_ 2026 1;
BA_ "GenSigSendType" SG_ 2026 Diag_OBD_BMS_RES 2;
BA_ "GenSigASIL"  SG_ 2026 Diag_OBD_BMS_RES 5;
BA_ "GenMsgSendType" BO_ 2030 1;
BA_ "GenSigSendType" SG_ 2030 Diag_OBD_CDU_RES 2;
BA_ "GenSigASIL"  SG_ 2030 Diag_OBD_CDU_RES 5;
BA_ "GenMsgSendType" BO_ 2027 1;
BA_ "GenSigSendType" SG_ 2027 Diag_OBD_RMCU_RES 2;
BA_ "GenSigASIL"  SG_ 2027 Diag_OBD_RMCU_RES 5;
BA_ "GenMsgSendType" BO_ 1819 1;
BA_ "GenSigSendType" SG_ 1819 Diag_ISG_REQ 2;
BA_ "GenSigASIL"  SG_ 1819 Diag_ISG_REQ 5;
BA_ "GenMsgSendType" BO_ 2020 1;
BA_ "GenSigSendType" SG_ 2020 Diag_OBD_ISG_REQ 2;
BA_ "GenSigASIL"  SG_ 2020 Diag_OBD_ISG_REQ 5;
BA_ "GenMsgSendType" BO_ 2018 1;
BA_ "GenSigSendType" SG_ 2018 Diag_BMS_REQ 2;
BA_ "GenSigASIL"  SG_ 2018 Diag_BMS_REQ 5;
BA_ "GenMsgSendType" BO_ 2022 1;
BA_ "GenSigSendType" SG_ 2022 Diag_CDU_REQ 2;
BA_ "GenSigASIL"  SG_ 2022 Diag_CDU_REQ 5;
BA_ "GenMsgSendType" BO_ 2019 1;
BA_ "GenSigSendType" SG_ 2019 Diag_RMCU_REQ 2;
BA_ "GenSigASIL"  SG_ 2019 Diag_RMCU_REQ 5;
VAL_ 1161 IGBT_ISGF_InvTemp 255 "Invalid" ;
VAL_ 1161 IGBT_TMf_InvTemp 255 "Invalid" ;
VAL_ 1161 ISGF_IdcAct 2047 "Invalid" ;
VAL_ 1161 ISGF_UdcAct 1023 "Invalid" ;
VAL_ 327 ISGF_IdcAct 2047 "Invalid" ;
VAL_ 327 ISGF_UdcAct 1023 "Invalid" ;
VAL_ 327 ISGF_ErrLvl 4 "Err_level4" 3 "Err_level3                                                                              " 2 "Err_level2                                                                              " 1 "Err_level1                                                                              " 0 "No Error                                                                                     " ;
VAL_ 327 ISGF_VoltageT30 63 "Invalid" ;
VAL_ 327 ISGF_DischargeState 3 "Discharge Failure" 2 "Discharge Completed" 1 "Discharging" 0 "No Discharge" ;
VAL_ 327 ISGF_TrqActDampingReq 2047 "Invalid" ;
VAL_ 327 ISGF_DampActive 1 "Active" 0 "Not Active" ;
VAL_ 327 ISGF_FlowReq 255 "Invalid" ;
VAL_ 327 ISGF_GateDrvSt 3 "ShortCircuit" 2 "Discharge" 1 "PWMrun" 0 "FreeWheel" ;
VAL_ 1400 ISG_SupplierCode 15 "Reserved" 14 "Reserved" 13 "Reserved" 12 "Reserved" 11 "Reserved" 10 "Reserved" 9 "Reserved" 8 "Reserved" 7 "Reserved" 6 "Reserved" 5 "Reserved" 4 "9GG" 3 "1RH" 2 "2CM" 1 "2AN" 0 "unkown" ;
VAL_ 264 EngineTorqAct 1023 "Invalid" ;
VAL_ 264 HCU_ISGF_TorqSet 2047 "Invalid" ;
VAL_ 264 HCU_ISGF_TorqMax 1023 "Invalid" ;
VAL_ 264 HCU_ISGF_TorqMin 1023 "Invalid" ;
VAL_ 264 HCU_ISGF_ModeReq 15 "reserved" 14 "reserved" 13 "reserved" 12 "reserved" 11 "reserved" 10 "reserved" 9 "Position Control" 8 "Cur Control(Reserved)" 7 "Emergency discharge" 6 "Power down (discharge)" 5 "Offset Calibration" 4 "Spd Control" 3 "Volt Control" 2 "Tq Control" 1 "HV Standby (disable)" 0 "LV Standby" ;
VAL_ 264 HCU_ISGF_SpdSet 65535 "Invalid" ;
VAL_ 264 NGenrMaxInTqMode 65535 "Invalid" ;
VAL_ 264 HCU_EngineSts 0 "Not Run" 1 "Run" ;
VAL_ 264 HCU_SleepAllow 1 "Not  Allowed" 0 "Allowed" ;
VAL_ 264 HCU_ISGF_DampReq 1 "Damping on" 0 "Damping off" ;
VAL_ 264 bEnaEmReq 0 "Disable" 1 "Enable" ;
VAL_ 818 HCU_ISGF_MaxTorqDampgCtl 255 "Invalid" ;
VAL_ 818 HCU_ISGF_MaxTorqGradient 16383 "Invalid" ;
VAL_ 818 HCU_ISGF_Uset 1023 "Invalid" ;
VAL_ 818 HCU_ISGF_Iset 2047 "Invalid" ;
VAL_ 818 HCU_ISGF_LimpPwrReq 255 "Invalid" ;
VAL_ 628 MaxDisCurrent_ISGF 32767 "Invalid" ;
VAL_ 628 MaxCharCurrent_ISGF 32767 "Invalid" ;
VAL_ 1034 HCU_EmPwr 255 "Invalid" ;
VAL_ 1034 HCU_VehicleState 15 "Reserved" 14 "Reserved" 13 "Reserved" 12 "Reserved" 11 "Reserved" 10 "Reserved" 9 "Reserved" 8 "Reserved" 7 "Reserved" 6 "Reserved" 5 "Reserved" 4 "Reserved" 3 "Charging" 2 "PowerUp" 1 "Sleep" 0 "Init" ;
VAL_ 1034 HCU_RunMode 3 "Reserved" 2 "ICE" 1 "HEV" 0 "EV" ;
VAL_ 1034 HCU_PwrTrnModeDisp 7 "Reserved" 6 "Reserved" 5 "REEV                                                                                          " 4 "Hybrid Mode" 3 "EV Only                                                                               " 2 "ICE Only" 1 "Regenerating                                                               " 0 "Static" ;
VAL_ 1034 HCU_IntelligentPowerSupply 7 "Reserved" 6 "Reserved    " 5 "Reserved    " 4 "Reserved" 3 "Charge Complete" 2 "Charging" 1 "No Request" 0 "Charge Inhibit" ;
VAL_ 1034 HCU_PowerModeFed 3 "EV+" 2 "HEV" 1 "EV " 0 "Not Active" ;
VAL_ 1034 HCU_LimpHomeMode 3 "REEV Only" 2 "ICE-Drive Only" 1 "E-Drive Only                                                               " 0 "Normal Mode" ;
VAL_ 1034 HCU_ISGRegenerateSts 1 "Active" 0 "Not Active" ;
VAL_ 1034 HCU_EmOverSpdWarn 1 "Warn" 0 "Not Warn" ;
VAL_ 1034 HCU_PowertrainFault 1 "Fault" 0 "No Fault" ;
VAL_ 1034 HCU_PrePTReady 1 "ON" 0 "OFF" ;
VAL_ 1034 HCU_PowerModeChangeFail 1 "FAIL" 0 "NOT FAIL" ;
VAL_ 1034 BMSH_MILReq 1 "Request" 0 "No request" ;
VAL_ 1034 TMF_EngMilLampReq 1 "Request" 0 "No request" ;
VAL_ 1034 TMR_EngMilLampReq 1 "Request" 0 "No request" ;
VAL_ 1034 HCU_MILReq 1 "Request" 0 "No request" ;
VAL_ 1034 HCU_HVReady 1 "LmpON" 0 "LmpOFF" ;
VAL_ 1034 HCU_PTReady 1 "LmpON" 0 "LmpOFF" ;
VAL_ 1034 HCU_ChargingSts 3 "Charge Complete" 2 "Run Charging" 1 "Stop Charging" 0 "No Charging" ;
VAL_ 1034 HCU_PtSts 15 "Reserved" 14 "Reserved" 13 "Reserved" 12 "Reserved" 11 "Parallel Regeneration" 10 "Parallel Generation" 9 "Parallel Drive" 8 "Motor Drag Engine" 7 "Idle No Charging" 6 "Idle Charging " 5 "Series Charging " 4 "Engine Stopping " 3 "Engine Starting " 2 "E Drive " 1 "Park Engine Off " 0 "Powertrain Not Active " ;
VAL_ 1034 HCU_InHbStrtRes 15 "reserve" 14 "reserve" 13 "reserve" 12 "reserve" 11 "reserve" 10 "reserve" 9 "reserve" 8 "gun connect" 7 "third start failed" 6 "out of speed" 5 "out of fuel" 4 "Insufficient torque" 3 "fuel door open" 2 "Hood open" 1 "PT fault" 0 "default" ;
VAL_ 1044 HCU_RangeAval 2047 "Invalid" ;
VAL_ 1044 HCU_EnergyFlow 31 "Reserved" 30 "Reserved" 29 "Reserved" 28 "Reserved" 27 "Reserved" 26 "Reserved" 25 "Reserved" 24 "Reserved" 23 "Reserved" 22 "Reserved" 21 "Reserved" 20 "4WD_ReGenerateBrakeByRear" 19 "4WD_ExtendRangeDisChargeByRear" 18 "4WD_ExtendRangeChargeByRear" 17 "4WD_EVByRear" 16 "DecelerateCharg" 15 "Charge" 14 "4WD_ReGenerateBrake" 13 "2WD_ReGenerateBrake" 12 "Parking_Generate" 11 "Running_Generate" 10 "Engine" 9 "4WD_Parallel" 8 "2WD_Parallel" 7 "4WD_ExtendRangeCharge" 6 "4WD_ExtendRangeDisCharge" 5 "2WD_ExtendRangeCharge" 4 "2WD_ExtendRangeDisCharge" 3 "4WD_EV" 2 "2WD_EV" 1 "Ready" 0 "Not Active" ;
VAL_ 1044 VCU_ForcedPrkgChrgModeFed 3 "Invalid" 2 "Off" 1 "On" 0 "Not Active          " ;
VAL_ 1044 HCU_SocManageFed 7 "Reserved" 6 "Reserved" 5 "Reserved" 4 "ForcedEVMode" 3 "SOC hold mode" 2 "Fuel priority mode" 1 "Pure electricity priority mode" 0 "Default" ;
VAL_ 1044 HCU_EnergyFlowREEV 31 "Reserved" 30 "Reserved" 29 "Reserved" 28 "Reserved" 27 "Reserved" 26 "Reserved" 25 "Reserved" 24 "Reserved" 23 "Reserved" 22 "Reserved" 21 "Reserved" 20 "Reserved" 19 "Reserved" 18 "Reserved" 17 "Reserved" 16 "Reserved" 15 "Reserved" 14 "Reserved" 13 "Reserved" 12 "Reserved" 11 "Reserved" 10 "Reserved" 9 "Reserved" 8 "Reserved" 7 "Reserved" 6 "ISGDrive" 5 "ISGDrive&BattDisChg" 4 "ISGDrive&BattChg" 3 "Running_Generate" 2 "Idle" 1 "during Start" 0 "OFF" ;
VAL_ 1044 HCU_CLMOBDClearReq 1 "Request" 0 "No Request" ;
VAL_ 1044 HCU_ReplaceWarmupCycle 1 "Active" 0 "Not Active" ;
VAL_ 1044 HCU_SetSOCFed 255 "Invalid" ;
VAL_ 1044 HCU_EmissionDetection 1 "Active" 0 "Not Active" ;
VAL_ 1044 VCU_BrakePedalStsValidData 1 "Not Valid" 0 "Valid" ;
VAL_ 1044 VCU_BrakePedalSts 1 "Applied" 0 "Not applied" ;
VAL_ 1044 HCU_2_G_LowBatteryInfo 3 "Reserved" 2 "Request" 1 "NoRequest" 0 "Not Active" ;
VAL_ 1044 HCU_2_G_LowBatteryLowFuelInfo 3 "Reserved" 2 "Request" 1 "NoRequest" 0 "Not Active" ;
VAL_ 1044 HCU_2_G_HighTempLimit 3 "Reserved" 2 "limit" 1 "Nolimit" 0 "Not Active" ;
VAL_ 1044 HCU_2_G_IntrptGpfRgtvSt 3 "Reserved" 2 "Reserved " 1 "Interrupt" 0 "Not Active" ;
VAL_ 1640 RMR_ISG 1 "Active" 0 "Inactive" ;
VAL_ 1640 ISG_Wakeup_Poweron 1 "Active" 0 "Inactive" ;
VAL_ 1640 ISG_Wakeup_NM 1 "Active" 0 "Inactive" ;
VAL_ 1640 ISG_Wakeup_Diag 1 "Active" 0 "Inactive" ;
VAL_ 1640 ISG_Awake_Poweron 1 "Active" 0 "Inactive" ;
VAL_ 1640 ISG_Awake_NM 1 "Active" 0 "Inactive" ;
VAL_ 1640 ISG_Awake_Diag 1 "Active" 0 "Inactive" ;
VAL_ 1640 ISG_Awake_Discharge 1 "Active" 0 "Inactive" ;
